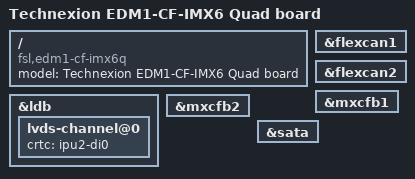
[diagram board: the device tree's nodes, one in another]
/*
 * Copyright 2015 Technexion Ltd.
 *
 * Author: Richard Hu <richard.hu@technexion.com>
 *
 * This program is free software; you can redistribute it and/or modify
 * it under the terms of the GNU General Public License version 2 as
 * published by the Free Software Foundation.
 *
 */

/dts-v1/;

#include <dt-bindings/interrupt-controller/irq.h>
#include "imx6q.dtsi"
#include "imx6qdl-edm1-cf-mimas.dtsi"

/ {
	model = "Technexion EDM1-CF-IMX6 Quad board";
	compatible = "fsl,edm1-cf-imx6q", "fsl,imx6q";
};

&ldb {
	lvds-channel@0 {
		crtc = "ipu2-di0";
	};
};

&flexcan1{
	status = "okay";
};

&flexcan2{
	status = "okay";
};

&mxcfb1 {
	status = "okay";
};

&mxcfb2 {
	status = "okay";
};

#if 0
&mxcfb3 {
	status = "okay";
};

&mxcfb4 {
	status = "okay";
};
#endif

&sata {
	status = "okay";
};
